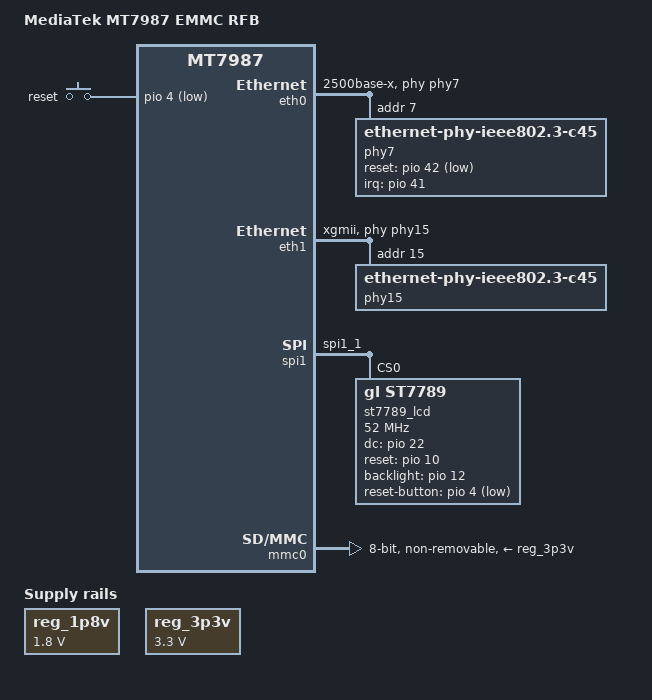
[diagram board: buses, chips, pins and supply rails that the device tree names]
// SPDX-License-Identifier: (GPL-2.0 OR MIT)

/dts-v1/;
#include "mt7987a.dtsi"
#include "mt7987-pinctrl.dtsi"
#include "mt7987a-u-boot.dtsi"
#include "mt7987-netsys-u-boot.dtsi"
#include <dt-bindings/input/input.h>
#include <dt-bindings/gpio/gpio.h>

/ {
	model = "MediaTek MT7987 EMMC RFB";
	compatible = "mediatek,mt7987a-emmc",
		     "mediatek,mt7987a", "mediatek,mt7987";

	chosen {
		bootargs = "console=ttyS0,115200n1 loglevel=8  \
			    earlycon=uart8250,mmio32,0x11000000 \
			    pci=pcie_bus_perf ubi.block=0,firmware \
			    root=/dev/fit0 rootwait";
	};

    config {
        bootcmd = "mtkboardboot";

        environment {
            lu = "mtkupgrade fip uboot-gl-be10000.bin";
            lf = "mtkupgrade fw openwrt-gl-be10000.bin";
        };
    };

	gpio-keys {
		compatible = "gpio-keys";

		reset {
			label = "reset";
			linux,code = <KEY_RESTART>;
			gpios = <&pio 4 GPIO_ACTIVE_LOW>;
			debounce-interval = <10>;
		};
	};

    reg_1p8v: regulator-1p8v {
		compatible = "regulator-fixed";
		regulator-name = "fixed-1.8V";
		regulator-min-microvolt = <1800000>;
		regulator-max-microvolt = <1800000>;
		regulator-boot-on;
		regulator-always-on;
	};

	reg_3p3v: regulator-3p3v {
		compatible = "regulator-fixed";
		regulator-name = "fixed-3.3V";
		regulator-min-microvolt = <3300000>;
		regulator-max-microvolt = <3300000>;
		regulator-boot-on;
		regulator-always-on;
	};
};

&eth0 {
	status = "okay";
	pinctrl-names = "default";
	pinctrl-0 = <&mdio0_pins>;
	phy-mode = "2500base-x";
	phy-handle = <&phy7>;

	phy7: phy@7 {
		compatible = "ethernet-phy-ieee802.3-c45";
		reg = <7>;
		reset-assert-us = <100000>;
		reset-deassert-us = <100000>;
		reset-gpios = <&pio 42 GPIO_ACTIVE_LOW>;
		interrupt-parent = <&pio>;
		interrupts = <41 IRQ_TYPE_LEVEL_LOW>;
		//realtek,aldps-enable;
	};
};

&eth1 {
	status = "okay";
	pinctrl-names = "i2p5gbe-led";
	pinctrl-0 = <&i2p5gbe_led0_pins>;
	phy-mode = "xgmii";
	phy-handle = <&phy15>;

	phy15: ethernet-phy@15 {
		compatible = "ethernet-phy-ieee802.3-c45";
		reg = <15>;
		phy-mode = "xgmii";
	};
};

&eth2 {
	status = "diabled";
};

&pio {
    spi1_1_pins: spi1_1-pins {
		mux {
			function = "spi";
			groups = "spi1_1";
		};
	};
};

&spi1 {
	pinctrl-0 = <&spi1_1_pins>;
	pinctrl-names = "default";
    #address-cells = <1>;
	#size-cells = <0>;
	status = "okay";
    must_tx;
	enhance_timing;
	dma_ext;
	ipm_design;
	tick_dly = <2>;
	sample_sel = <0>;

	st7789_lcd: st7789@0 {
		compatible = "gl,st7789";
		reg = <0>;
		spi-max-frequency = <52000000>;
		dc-gpios = <&pio 22 GPIO_ACTIVE_HIGH>;
		reset-gpios = <&pio 10 GPIO_ACTIVE_HIGH>;
		backlight-gpios = <&pio 12 GPIO_ACTIVE_HIGH>;
		/* Same pin/polarity as gpio-keys /reset */
		reset-button-gpios = <&pio 4 GPIO_ACTIVE_LOW>;
	};
};

&i2c0 {
	status = "disabled";
};

&mmc0 {
	pinctrl-names = "default", "state_uhs";
	pinctrl-0 = <&mmc_pins_default>;
	pinctrl-1 = <&mmc_pins_uhs>;
	bus-width = <8>;
	max-frequency = <26000000>;
	cap-mmc-highspeed;
	mmc-hs200-1_8v;
	mmc-hs400-1_8v;
	hs400-ds-delay = <0x12814>;
	vqmmc-supply = <&reg_3p3v>;
	vmmc-supply = <&reg_3p3v>;
	non-removable;
	no-sd;
	no-sdio;
	status = "okay";
};
